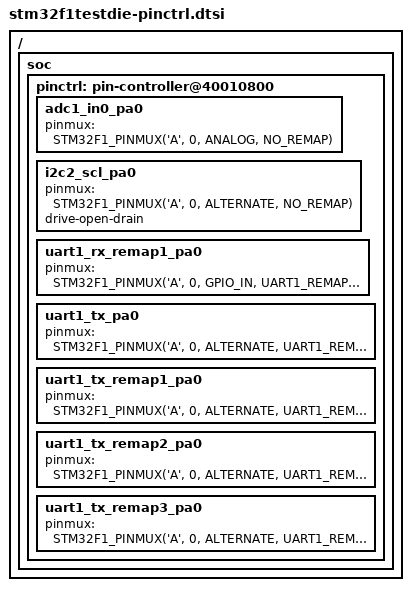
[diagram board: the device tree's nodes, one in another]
/*
 * NOTE: Autogenerated file using genpinctrl.py
 *
 * SPDX-License-Identifier: Apache-2.0
 */

#include <zephyr/dt-bindings/pinctrl/stm32f1-pinctrl.h>

/ {
	soc {
		pinctrl: pin-controller@40010800 {

			/* ADC_IN */

			/omit-if-no-ref/ adc1_in0_pa0: adc1_in0_pa0 {
				pinmux = <STM32F1_PINMUX('A', 0, ANALOG, NO_REMAP)>;
			};

			/* I2C_SCL */

			/omit-if-no-ref/ i2c2_scl_pa0: i2c2_scl_pa0 {
				pinmux = <STM32F1_PINMUX('A', 0, ALTERNATE, NO_REMAP)>;
				drive-open-drain;
			};

			/* UART_RX / USART_RX */

			/omit-if-no-ref/ uart1_rx_remap1_pa0: uart1_rx_remap1_pa0 {
				pinmux = <STM32F1_PINMUX('A', 0, GPIO_IN, UART1_REMAP1)>;
			};

			/* UART_TX / USART_TX */

			/omit-if-no-ref/ uart1_tx_pa0: uart1_tx_pa0 {
				pinmux = <STM32F1_PINMUX('A', 0, ALTERNATE, UART1_REMAP0)>;
			};

			/omit-if-no-ref/ uart1_tx_remap1_pa0: uart1_tx_remap1_pa0 {
				pinmux = <STM32F1_PINMUX('A', 0, ALTERNATE, UART1_REMAP1)>;
			};

			/omit-if-no-ref/ uart1_tx_remap2_pa0: uart1_tx_remap2_pa0 {
				pinmux = <STM32F1_PINMUX('A', 0, ALTERNATE, UART1_REMAP2)>;
			};

			/omit-if-no-ref/ uart1_tx_remap3_pa0: uart1_tx_remap3_pa0 {
				pinmux = <STM32F1_PINMUX('A', 0, ALTERNATE, UART1_REMAP3)>;
			};

		};
	};
};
